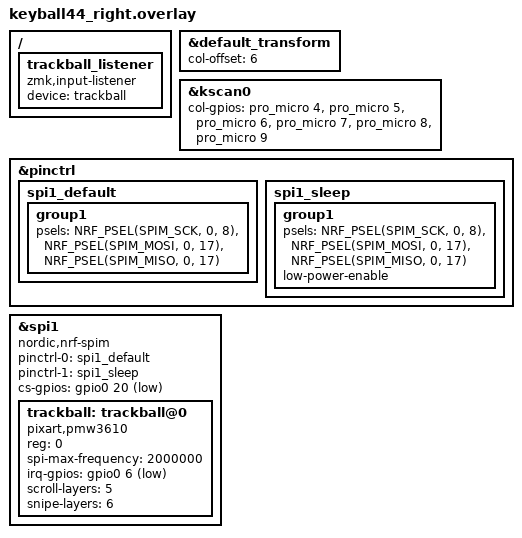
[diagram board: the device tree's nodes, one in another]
/*
 * Copyright (c) 2020 ZMK Contributors
 *
 * SPDX-License-Identifier: MIT
 */
 
#include "keyball44.dtsi"

&default_transform {
    col-offset = <6>;
};

&kscan0 {
	col-gpios
       = <&pro_micro 4 (GPIO_ACTIVE_HIGH)> // COL0 
        , <&pro_micro 5 (GPIO_ACTIVE_HIGH)> // COL1 
        , <&pro_micro 6 (GPIO_ACTIVE_HIGH)> // COL2 
        , <&pro_micro 7 (GPIO_ACTIVE_HIGH)> // COL3 
	, <&pro_micro 8 (GPIO_ACTIVE_HIGH)> // COL1 
        , <&pro_micro 9 (GPIO_ACTIVE_HIGH)> // COL2 
    ;
};

&pinctrl {
    spi1_default: spi1_default {
        group1 {
            psels = <NRF_PSEL(SPIM_SCK, 0, 8)>,
                <NRF_PSEL(SPIM_MOSI, 0, 17)>,
                <NRF_PSEL(SPIM_MISO, 0, 17)>;
        };
    };

    spi1_sleep: spi1_sleep {
        group1 {
            psels = <NRF_PSEL(SPIM_SCK, 0, 8)>,
                <NRF_PSEL(SPIM_MOSI, 0, 17)>,
                <NRF_PSEL(SPIM_MISO, 0, 17)>;
            low-power-enable;
        };
    };
};

&spi1 {
    status = "okay";
    compatible = "nordic,nrf-spim";
    pinctrl-0 = <&spi1_default>;
    pinctrl-1 = <&spi1_sleep>;
    pinctrl-names = "default", "sleep";
    cs-gpios = <&gpio0 20 GPIO_ACTIVE_LOW>;

    trackball: trackball@0 {
        status = "okay";
        compatible = "pixart,pmw3610";
        reg = <0>;
        spi-max-frequency = <2000000>;
        irq-gpios = <&gpio0 6 (GPIO_ACTIVE_LOW | GPIO_PULL_UP)>;
	scroll-layers = <5>;
	snipe-layers = <6>;
    };
};

/ {
  trackball_listener {
    compatible = "zmk,input-listener";
    device = <&trackball>;

  };
};
